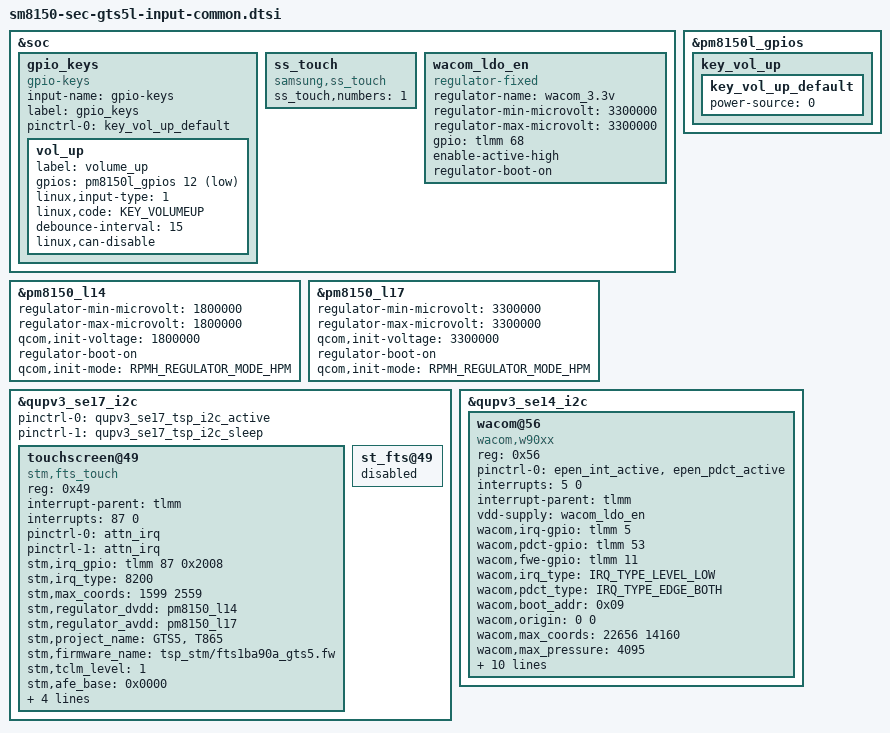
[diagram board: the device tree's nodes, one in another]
/* Copyright (c) 2016-2017, The Linux Foundation. All rights reserved.
 *
 * This program is free software; you can redistribute it and/or modify
 * it under the terms of the GNU General Public License version 2 and
 * only version 2 as published by the Free Software Foundation.
 *
 * This program is distributed in the hope that it will be useful,
 * but WITHOUT ANY WARRANTY; without even the implied warranty of
 * MERCHANTABILITY or FITNESS FOR A PARTICULAR PURPOSE.  See the
 * GNU General Public License for more details.
 */

#include <dt-bindings/input/input.h>
#include <dt-bindings/interrupt-controller/irq.h>
#include <dt-bindings/gpio/gpio.h>

/delete-node/ &gpio_keys;
&soc {
	gpio_keys: gpio_keys {
		status = "ok";
		compatible = "gpio-keys";
		input-name = "gpio-keys";
		label = "gpio_keys";

		pinctrl-names = "default";
		pinctrl-0 = <&key_vol_up_default>;

		vol_up {
			label = "volume_up";
			gpios = <&pm8150l_gpios 12 GPIO_ACTIVE_LOW>;
			linux,input-type = <1>;
			linux,code = <KEY_VOLUMEUP>;
			debounce-interval = <15>;
			linux,can-disable;
		};
	};

	ss_touch {
		compatible = "samsung,ss_touch";
		ss_touch,numbers = <1>;
	};

	wacom_ldo_en: wacom_ldo_en {
		compatible = "regulator-fixed";
		regulator-name = "wacom_3.3v";
		regulator-min-microvolt = <3300000>;
		regulator-max-microvolt = <3300000>;
		gpio = <&tlmm 68 0>;
		enable-active-high;
		regulator-boot-on;
	};
};

&pm8150l_gpios {
	key_vol_up {
		key_vol_up_default: key_vol_up_default {
			power-source = <0>;
		};
	};
};

&pm8150_l14 {
	regulator-min-microvolt = <1800000>;
	regulator-max-microvolt = <1800000>;
	qcom,init-voltage = <1800000>;
	regulator-boot-on;
	qcom,init-mode = <RPMH_REGULATOR_MODE_HPM>;
};

&pm8150_l17 {
	regulator-min-microvolt = <3300000>;
	regulator-max-microvolt = <3300000>;
	qcom,init-voltage = <3300000>;
	regulator-boot-on;
	qcom,init-mode = <RPMH_REGULATOR_MODE_HPM>;
};

&qupv3_se17_i2c {
	pinctrl-0 = <&qupv3_se17_tsp_i2c_active>;
	pinctrl-1 = <&qupv3_se17_tsp_i2c_sleep>;
	status = "ok";

	/* stm */
	touchscreen@49 {
		status = "okay";
		compatible = "stm,fts_touch";
		reg = <0x49>;
		interrupt-parent = <&tlmm>;
		interrupts = <87 0>;
		pinctrl-names = "on_state", "off_state";
		pinctrl-0 = <&attn_irq>;
		pinctrl-1 = <&attn_irq>;
		stm,irq_gpio = <&tlmm 87 0x2008>;
		stm,irq_type = <8200>;
		stm,max_coords = <1599 2559>;	/* x y */
		stm,regulator_dvdd = "pm8150_l14";
		stm,regulator_avdd = "pm8150_l17";
		stm,project_name = "GTS5", "T865";
		stm,firmware_name = "tsp_stm/fts1ba90a_gts5.fw";
		stm,tclm_level = <1>;
		stm,afe_base = <0x0000>;
		stm,enable_settings_aot;
		support_dex_mode;
		stm,ss_touch_num = <1>;
		stm,enable_vbus_noti;
	};

	st_fts@49 {
		status = "disabled";
	};
};

&qupv3_se14_i2c {
	status = "ok";

	wacom@56 {
		compatible = "wacom,w90xx";
		reg = <0x56>;
		pinctrl-names = "default";
		pinctrl-0 = <&epen_int_active &epen_pdct_active>;
		interrupts = <5 0>;
		interrupt-parent = <&tlmm>;
		vdd-supply = <&wacom_ldo_en>;
		/* gpios */
		wacom,irq-gpio = <&tlmm 5 0>;
		wacom,pdct-gpio = <&tlmm 53 0>;
		wacom,fwe-gpio = <&tlmm 11 0>;
		wacom,irq_type = <IRQ_TYPE_LEVEL_LOW>;
		wacom,pdct_type = <IRQ_TYPE_EDGE_BOTH>;
		/* features */
		wacom,boot_addr = <0x09>;
		wacom,origin = <0 0>; /* x y */
		//wacom,max_coords = <14563 7085>; /* x y */
		wacom,max_coords = <22656 14160>;
		wacom,max_pressure = <4095>;
		wacom,max_x_tilt = <63>;
		wacom,max_y_tilt = <63>;
		wacom,max_height = <255>;
		wacom,project_name = "GTS5", "T865";
		//wacom,invert = <1 0 1>; /* x y switch */
		wacom,invert = <0 1 1>;
		wacom,ic_type = <9021>;
		wacom,fw_path = "epen/w9021_gts5l.fw";
		wacom,module_ver = <0x2>; /* this value use to distinguish open/short test (0x1 : only open test, 0x2: open/short test) */
		wacom,support_aop_mode = "1"; /* S-note want to check to use aop */
		wacom,use_garage;
	};
};
